# Operational_Amplifier_1_1 register map
Vendor: Texas Instruments
Peripheral module from a debugger description file (folder msp430).
Registers are 16-bit, read-write, reset 0x0 unless marked. A register's access mark holds for its fields unless they carry their own. Offsets are as the file gives them; lines under a group give offsets from that group; [hi:lo] are bit positions; {n}, {i} and the like mark numbered series; 'fields as' and 'values as' point back to an identical list; <NAME> marks a mode.

## Operational_Amplifier_1
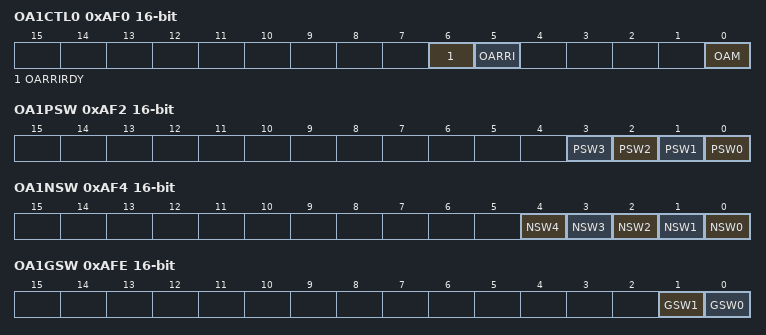
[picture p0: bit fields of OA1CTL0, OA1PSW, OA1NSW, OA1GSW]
0xAF0 OA1CTL0 — OA1 Control register 0
  [6] OARRIRDY — Rail-to-rail input ready status
  [5] OARRI — Rail-to-rail input enable
  [0] OAM — Amplifier mode selection
0xAF2 OA1PSW — OA1 Positive Input Terminal Switches
  [n] PSW{n} (n=0..3) — Positive input terminal switch {n} control
0xAF4 OA1NSW — OA1 Negative Input Terminal Switches
  [n] NSW{n} (n=0..4) — Negative input terminal switch {n} control
0xAFE OA1GSW — OA1 Ground Switches
  [1] GSW1 — Ground switch 1
  [0] GSW0 — Ground switch 0
